# STM32H523 register map
File version: 1.3
CPU: CM33 r0p0, little endian, MPU, FPU, 4 interrupt priority bits
Registers are 32-bit, read-write, reset 0x0 unless marked. A register's access mark holds for its fields unless they carry their own. Offsets are from the block's base; [hi:lo] are bit positions; {n}, {i} and the like mark numbered series; 'fields as' and 'values as' point back to an identical list.

## ICACHE — ICACHE register block
Base 0x40030400
Same registers: ICACHE_S 0x50030400
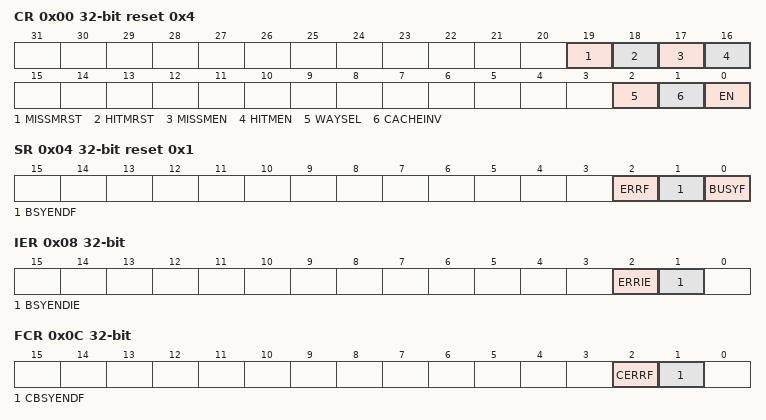
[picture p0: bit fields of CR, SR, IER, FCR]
0x00 CR reset 0x4 — ICACHE control register
  [19] MISSMRST — miss monitor reset
  [18] HITMRST — hit monitor reset
  [17] MISSMEN — miss monitor enable
  [16] HITMEN — hit monitor enable
  [2] WAYSEL — cache associativity mode selection
  [1] CACHEINV wo — cache invalidation
  [0] EN — enable
0x04 SR ro reset 0x1 — ICACHE status register
  [2] ERRF — cache error flag
  [1] BSYENDF — busy end flag
  [0] BUSYF — busy flag
0x08 IER — ICACHE interrupt enable register
  [2] ERRIE — interrupt enable on cache error
  [1] BSYENDIE — interrupt enable on busy end
0x0C FCR wo — ICACHE flag clear register
  [2] CERRF — clear cache error flag
  [1] CBSYENDF — clear busy end flag
0x10 HMONR ro — ICACHE hit monitor register
  [31:0] HITMON — cache hit monitor counter
0x14 MMONR ro — ICACHE miss monitor register
  [15:0] MISSMON — cache miss monitor counter
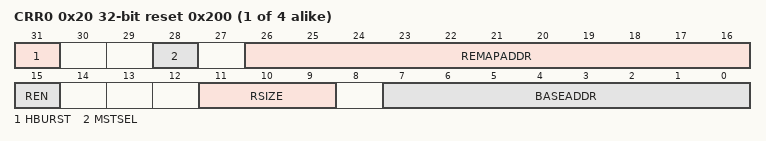
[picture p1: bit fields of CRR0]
{0x20+4i} CRR{i} reset 0x200 (i=0..3) — ICACHE region {i} configuration register
  [31] HBURST — output burst type for region x
  [28] MSTSEL — AHB cache master selection for region x
  [26:16] REMAPADDR — remapped address for region x
  [15] REN — enable for region x
  [11:9] RSIZE — size for region x
  [7:0] BASEADDR — base address for region x

## IWDG — IWDG address block description
Base 0x40003000
Same registers: IWDG_S 0x50003000
0x00 KR 16-bit wo — IWDG key register
  [15:0] KEY — Key value (write only, read 0x0000)
    0x5555=Unlock (Enable access to PR, RLR and WINR registers); 0xAAAA=Feed watchdog with RLR register value; 0xCCCC=Start the watchdog
0x04 PR 16-bit — IWDG prescaler register
  [3:0] PR — Prescaler divider
    0=DivideBy4 (Divider /4); 1=DivideBy8 (Divider /8); 2=DivideBy16 (Divider /16); 3=DivideBy32 (Divider /32); 4=DivideBy64 (Divider /64); 5=DivideBy128 (Divider /128); 6=DivideBy256 (Divider /256); 7=DivideBy512 (Divider /512); other=DivideBy1024 (Divider /1024)
0x08 RLR 16-bit reset 0xFFF — IWDG reload register
  [11:0] RL — Watchdog counter reload value
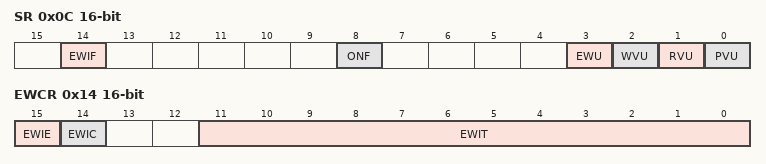
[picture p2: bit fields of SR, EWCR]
0x0C SR 16-bit ro — IWDG status register
  [14] EWIF — Watchdog early interrupt flag
    0=NotPending (No pending interrupt); 1=Pending (Interrupt pending)
  [8] ONF — Watchdog enable status bit
    0=NotActivated (IWDG is not activated); 1=Activated (IWDG is activated)
  [3] EWU — Watchdog interrupt comparator value update
    0=Idle (No update on-going); 1=Busy (Update on-going)
  [2] WVU — Watchdog counter window value update
    0=Idle (No update on-going); 1=Busy (Update on-going)
  [1] RVU — Watchdog counter reload value update
    0=Idle (No update on-going); 1=Busy (Update on-going)
  [0] PVU — Watchdog prescaler value update
    0=Idle (No update on-going); 1=Busy (Update on-going)
0x10 WINR 16-bit reset 0xFFF — IWDG window register
  [11:0] WIN — Watchdog counter window value
0x14 EWCR 16-bit — IWDG early wake-up interrupt register
  [15] EWIE — Watchdog early interrupt enable
  [14] EWIC wo — Watchdog early interrupt acknowledge
  [11:0] EWIT — Watchdog counter window value

## RAMCFG — RAMCFG address block description
Base 0x40026000
Same registers: RAMCFG_S 0x50026000
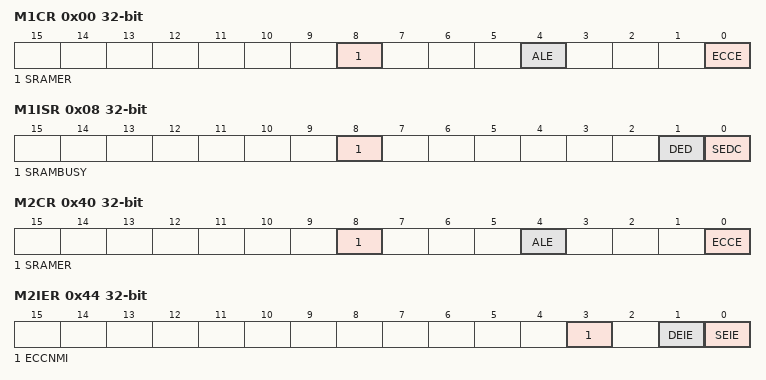
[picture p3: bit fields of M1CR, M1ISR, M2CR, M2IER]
0x00 M1CR (reset mask 0xFFFFFFF0) — RAMCFG memory 1 control register
  [8] SRAMER — SRAM erase
  [4] ALE — Address latch enable
  [0] ECCE — ECC enable.
0x08 M1ISR ro — RAMCFG memory interrupt status register
  [8] SRAMBUSY — SRAM busy with erase operation
  [1] DED — ECC double error detected
  [0] SEDC — ECC single error detected and corrected
0x28 M1ERKEYR wo — RAMCFG memory 1 erase key register
  [7:0] ERASEKEY — Erase write protection key
0x40 M2CR (reset mask 0xFFFFFFF0) — RAMCFG memory 2 control register
  fields as M1CR
0x44 M2IER — RAMCFG memory 2 interrupt enable register
  [3] ECCNMI — Double error NMI
  [1] DEIE — ECC double error interrupt enable
  [0] SEIE — ECC single error interrupt enable
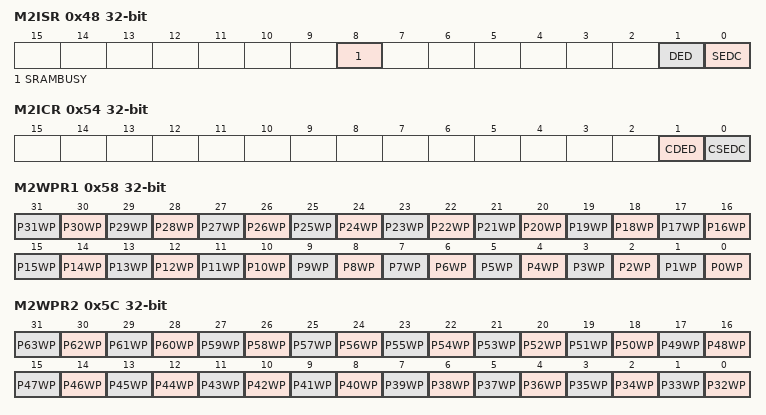
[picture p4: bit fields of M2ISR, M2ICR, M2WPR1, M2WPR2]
0x48 M2ISR ro — RAMCFG memory interrupt status register
  fields as M1ISR
0x4C M2SEAR ro — RAMCFG memory 2 ECC single error address register
  [31:0] ESEA — ECC single error address
0x50 M2DEAR ro — RAMCFG memory 2 ECC double error address register
  [31:0] EDEA — ECC double error address
0x54 M2ICR — RAMCFG memory 2 interrupt clear register 2
  [1] CDED — Clear ECC double error detected
  [0] CSEDC — Clear ECC single error detected and corrected
0x58 M2WPR1 — RAMCFG memory 2 write protection register 1
  [n] P{n}WP (n=0..31) — SRAM2 1-Kbyte page y write protection
0x5C M2WPR2 — RAMCFG memory 2 write protection register 2
  [n-32] P{n}WP (n=32..63) — SRAM2 1-Kbyte page y write protection
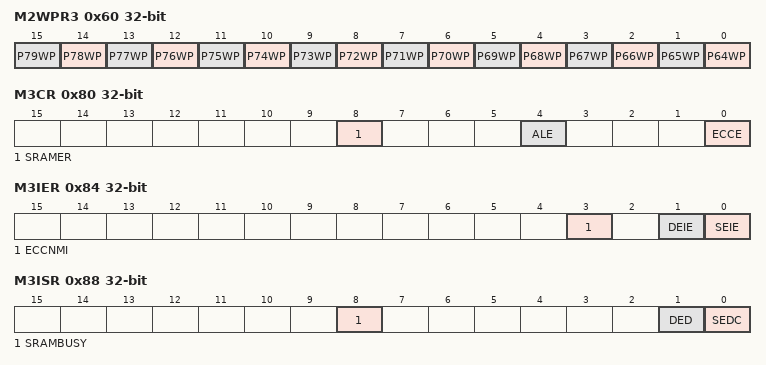
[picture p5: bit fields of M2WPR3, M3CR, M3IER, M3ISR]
0x60 M2WPR3 — RAMCFG memory 2 write protection register 3
  [n-64] P{n}WP (n=64..79) — SRAM2 1-Kbyte page y write protection
0x64 M2ECCKEYR wo — RAMCFG memory 2 ECC key register
  [7:0] ECCKEY — ECC write protection key
0x68 M2ERKEYR wo — RAMCFG memory 2 erase key register
  [7:0] ERASEKEY — Erase write protection key
0x80 M3CR (reset mask 0xFFFFFFF0) — RAMCFG memory 3 control register
  fields as M1CR
0x84 M3IER — RAMCFG memory 3 interrupt enable register
  fields as M2IER
0x88 M3ISR ro — RAMCFG memory interrupt status register
  fields as M1ISR
0x8C M3SEAR ro — RAMCFG memory 3 ECC single error address register
  [31:0] ESEA — ECC single error address
0x90 M3DEAR ro — RAMCFG memory 3 ECC double error address register
  [31:0] EDEA — ECC double error address
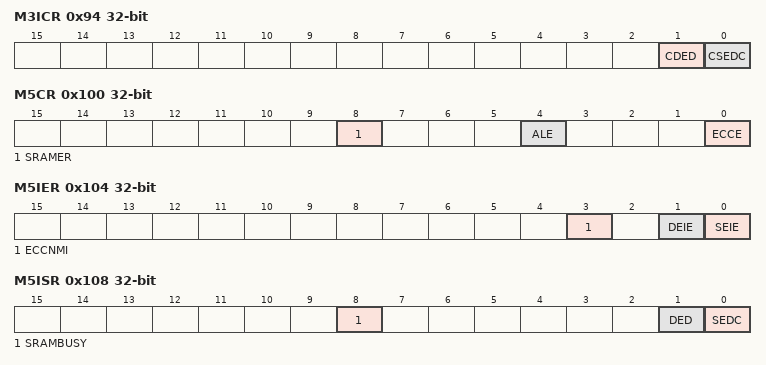
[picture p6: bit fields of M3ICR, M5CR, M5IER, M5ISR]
0x94 M3ICR — RAMCFG memory 3 interrupt clear register 3
  fields as M2ICR
0xA4 M3ECCKEYR wo — RAMCFG memory 3 ECC key register
  [7:0] ECCKEY — ECC write protection key
0xA8 M3ERKEYR wo — RAMCFG memory 3 erase key register
  [7:0] ERASEKEY — Erase write protection key
0xE8 M4ERKEYR wo — RAMCFG memory 4 erase key register
  [7:0] ERASEKEY — Erase write protection key
0x100 M5CR (reset mask 0xFFFFFFF0) — RAMCFG memory 5 control register
  fields as M1CR
0x104 M5IER — RAMCFG memory 5 interrupt enable register
  fields as M2IER
0x108 M5ISR ro — RAMCFG memory interrupt status register
  fields as M1ISR
0x10C M5SEAR ro — RAMCFG memory 5 ECC single error address register
  [31:0] ESEA — ECC single error address
0x110 M5DEAR ro — RAMCFG memory 5 ECC double error address register
  [31:0] EDEA — ECC double error address
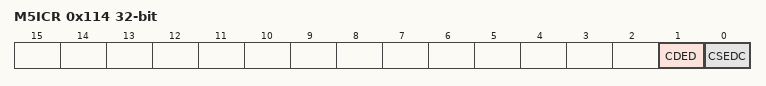
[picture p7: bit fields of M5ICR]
0x114 M5ICR — RAMCFG memory 5 interrupt clear register 5
  fields as M2ICR
0x124 M5ECCKEYR wo — RAMCFG memory 5 ECC key register
  [7:0] ECCKEY — ECC write protection key
0x128 M5ERKEYR wo — RAMCFG memory 5 erase key register
  [7:0] ERASEKEY — Erase write protection key
